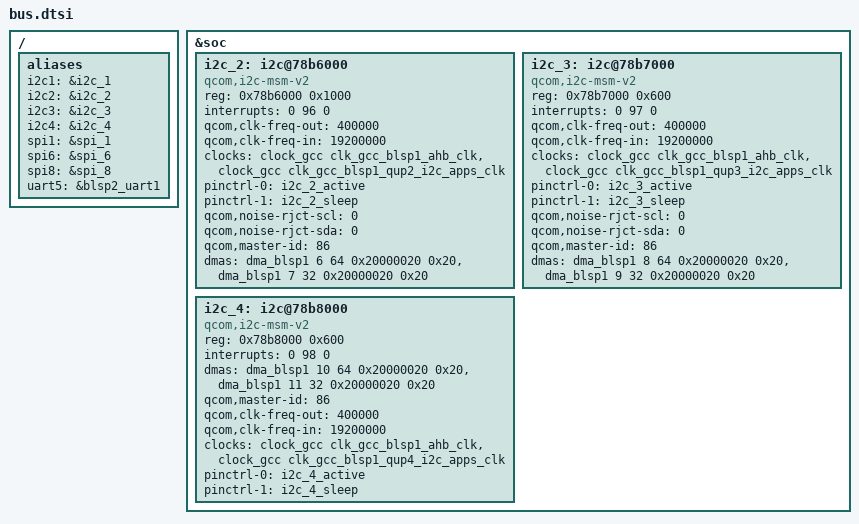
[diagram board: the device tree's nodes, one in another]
/ {
	aliases {
		i2c1 = &i2c_1;
		i2c2 = &i2c_2;
		i2c3 = &i2c_3;
		i2c4 = &i2c_4;
		spi1 = &spi_1;
		spi6 = &spi_6;
		spi8 = &spi_8;
		uart5 = &blsp2_uart1;
		/delete-property/ spi3;
		/delete-property/ i2c5;
	};
};

&soc {
	/delete-node/ i2c@7af5000; 
	/delete-node/ spi@78b7000;

	i2c_2: i2c@78b6000 { /* BLSP1 QUP2 */
		compatible = "qcom,i2c-msm-v2";
		#address-cells = <1>;
		#size-cells = <0>;
		reg-names = "qup_phys_addr";
		reg = <0x78b6000 0x1000>;
		interrupt-names = "qup_irq";
		interrupts = <0 96 0>;
		qcom,clk-freq-out = <400000>;
		qcom,clk-freq-in  = <19200000>;
		clock-names = "iface_clk", "core_clk";
		clocks = <&clock_gcc clk_gcc_blsp1_ahb_clk>,
			<&clock_gcc clk_gcc_blsp1_qup2_i2c_apps_clk>;

		pinctrl-names = "i2c_active", "i2c_sleep";
		pinctrl-0 = <&i2c_2_active>;
		pinctrl-1 = <&i2c_2_sleep>;
		qcom,noise-rjct-scl = <0>;
		qcom,noise-rjct-sda = <0>;
		qcom,master-id = <86>;
		dmas = <&dma_blsp1 6 64 0x20000020 0x20>,
			<&dma_blsp1 7 32 0x20000020 0x20>;
		dma-names = "tx", "rx";
		};

	i2c_3: i2c@78b7000 { /* BLSP1 QUP3 */
		status = "okay";
		compatible = "qcom,i2c-msm-v2";
		#address-cells = <1>;
		#size-cells = <0>;
		reg-names = "qup_phys_addr";
		reg = <0x78b7000 0x600>;
		interrupt-names = "qup_irq";
		interrupts = <0 97 0>;
		qcom,clk-freq-out = <400000>;
		qcom,clk-freq-in  = <19200000>;
		clock-names = "iface_clk", "core_clk";
		clocks = <&clock_gcc clk_gcc_blsp1_ahb_clk>,
			<&clock_gcc clk_gcc_blsp1_qup3_i2c_apps_clk>;

		pinctrl-names = "i2c_active", "i2c_sleep";
		pinctrl-0 = <&i2c_3_active>;
		pinctrl-1 = <&i2c_3_sleep>;
		qcom,noise-rjct-scl = <0>;
		qcom,noise-rjct-sda = <0>;
		qcom,master-id = <86>;
		dmas = <&dma_blsp1 8 64 0x20000020 0x20>,
			<&dma_blsp1 9 32 0x20000020 0x20>;
		dma-names = "tx", "rx";
		};

	/* SensorHub Bus */
	i2c_4: i2c@78b8000 {
		/* BLSP1 QUP4, however QC refers to this address as:
		   HWID BLSP4 - BLSP1 QUP3
		*/
		status = "okay";
		compatible = "qcom,i2c-msm-v2";
		#address-cells = <1>;
		#size-cells = <0>;
		reg-names = "qup_phys_addr";
		reg = <0x78b8000 0x600>;
		interrupt-names = "qup_irq";
		interrupts = <0 98 0>;
		dmas = <&dma_blsp1 10 64 0x20000020 0x20>,
			<&dma_blsp1 11 32 0x20000020 0x20>;
		dma-names = "tx", "rx";
		qcom,master-id = <86>;
		qcom,clk-freq-out = <400000>;
		qcom,clk-freq-in  = <19200000>;
		clock-names = "iface_clk", "core_clk";
		clocks = <&clock_gcc clk_gcc_blsp1_ahb_clk>,
			 <&clock_gcc clk_gcc_blsp1_qup4_i2c_apps_clk>;
		pinctrl-names = "i2c_active", "i2c_sleep";
		pinctrl-0 = <&i2c_4_active>;
		pinctrl-1 = <&i2c_4_sleep>;
		};
};
